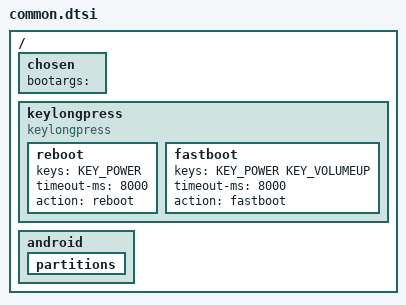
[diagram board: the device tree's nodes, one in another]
/*
 * Device Tree Source for the Android
 *
 * Copyright (C) 2018 GlobalLogic
 *
 * This file is licensed under the terms of the GNU General Public License
 * version 2.  This program is licensed "as is" without any warranty of any
 * kind, whether express or implied.
 */

/ {
	chosen {
		bootargs = "";
	};

	keylongpress {
		compatible = "keylongpress";
		reboot {
			keys = <KEY_POWER>;
			timeout-ms = <8000>;
			action = "reboot";
		};

		fastboot {
			keys = <KEY_POWER KEY_VOLUMEUP>;
			timeout-ms = <8000>;
			action = "fastboot";
		};
	};

	android {
		partitions {
			/* Should be filled by U-boot at boottime */
		};
	};
};
